# bao1x register map
Vendor: baochip; File version: 1.0
Registers are 32-bit, read-write, reset 0x0 unless marked. A register's access mark holds for its fields unless they carry their own. Offsets are from the block's base; [hi:lo] are bit positions; <NAME> marks a mode.

## UDMA_SCIF
Base 0x50111000
0x00 REG_RX_SADDR — See `udma_scif_reg.sv <https://github.com/baochip/baochip-1x/blob/main/rtl/modul es/ifsub/rtl/udma_scif_reg.sv>`__
  [11:0] r_rx_startaddr
0x04 REG_RX_SIZE — See `udma_scif_reg.sv <https://github.com/baochip/baochip-1x/blob/main/rtl/modul es/ifsub/rtl/udma_scif_reg.sv>`__
  [15:0] r_rx_size
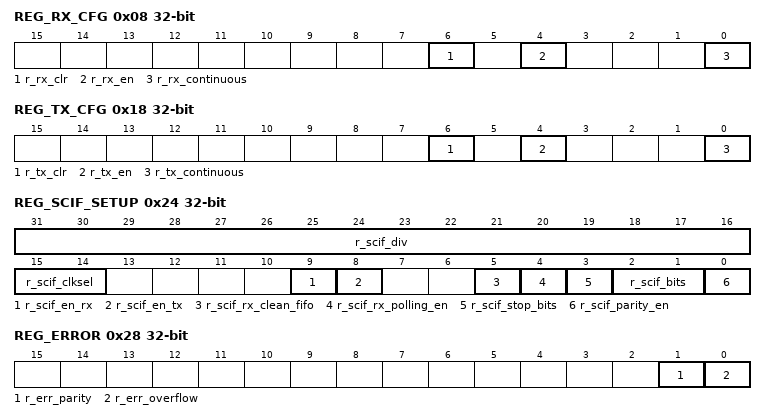
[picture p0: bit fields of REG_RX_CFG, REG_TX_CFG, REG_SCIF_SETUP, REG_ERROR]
0x08 REG_RX_CFG — See `udma_scif_reg.sv <https://github.com/baochip/baochip-1x/blob/main/rtl/modul es/ifsub/rtl/udma_scif_reg.sv>`__
  [6] r_rx_clr, [4] r_rx_en, [0] r_rx_continuous
0x10 REG_TX_SADDR — See `udma_scif_reg.sv <https://github.com/baochip/baochip-1x/blob/main/rtl/modul es/ifsub/rtl/udma_scif_reg.sv>`__
  [11:0] r_tx_startaddr
0x14 REG_TX_SIZE — See `udma_scif_reg.sv <https://github.com/baochip/baochip-1x/blob/main/rtl/modul es/ifsub/rtl/udma_scif_reg.sv>`__
  [15:0] r_tx_size
0x18 REG_TX_CFG — See `udma_scif_reg.sv <https://github.com/baochip/baochip-1x/blob/main/rtl/modul es/ifsub/rtl/udma_scif_reg.sv>`__
  [6] r_tx_clr, [4] r_tx_en, [0] r_tx_continuous
0x20 REG_STATUS — See `udma_scif_reg.sv <https://github.com/baochip/baochip-1x/blob/main/rtl/modul es/ifsub/rtl/udma_scif_reg.sv>`__
  [0] status_i
0x24 REG_SCIF_SETUP — See `udma_scif_reg.sv <https://github.com/baochip/baochip-1x/blob/main/rtl/modul es/ifsub/rtl/udma_scif_reg.sv>`__
  [31:16] r_scif_div, [15:14] r_scif_clksel, [9] r_scif_en_rx, [8] r_scif_en_tx, [5] r_scif_rx_clean_fifo, [4] r_scif_rx_polling_en, [3] r_scif_stop_bits, [2:1] r_scif_bits, [0] r_scif_parity_en
0x28 REG_ERROR — See `udma_scif_reg.sv <https://github.com/baochip/baochip-1x/blob/main/rtl/modul es/ifsub/rtl/udma_scif_reg.sv>`__
  [1] r_err_parity, [0] r_err_overflow
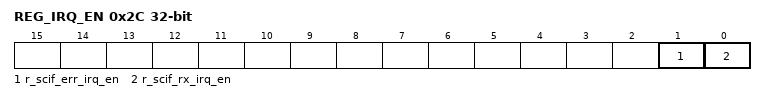
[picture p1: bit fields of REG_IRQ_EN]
0x2C REG_IRQ_EN — See `udma_scif_reg.sv <https://github.com/baochip/baochip-1x/blob/main/rtl/modul es/ifsub/rtl/udma_scif_reg.sv>`__
  [1] r_scif_err_irq_en, [0] r_scif_rx_irq_en
0x30 REG_VALID — See `udma_scif_reg.sv <https://github.com/baochip/baochip-1x/blob/main/rtl/modul es/ifsub/rtl/udma_scif_reg.sv>`__
  [0] r_scif_rx_data_valid
0x34 REG_DATA — See `udma_scif_reg.sv <https://github.com/baochip/baochip-1x/blob/main/rtl/modul es/ifsub/rtl/udma_scif_reg.sv>`__
  [7:0] r_scif_rx_data
0x38 REG_SCIF_ETU — See `udma_scif_reg.sv <https://github.com/baochip/baochip-1x/blob/main/rtl/modul es/ifsub/rtl/udma_scif_reg.sv>`__
  [15:0] r_scif_etu

## UDMA_SPIS_0
Base 0x50112000
Same registers: UDMA_SPIS_1 0x50113000
0x00 REG_RX_SADDR — See `udma_spis_reg.sv <https://github.com/baochip/baochip-1x/blob/main/rtl/modul es/ifsub/rtl/udma_spis_reg.sv>`__
  [11:0] r_rx_startaddr
0x04 REG_RX_SIZE — See `udma_spis_reg.sv <https://github.com/baochip/baochip-1x/blob/main/rtl/modul es/ifsub/rtl/udma_spis_reg.sv>`__
  [15:0] r_rx_size
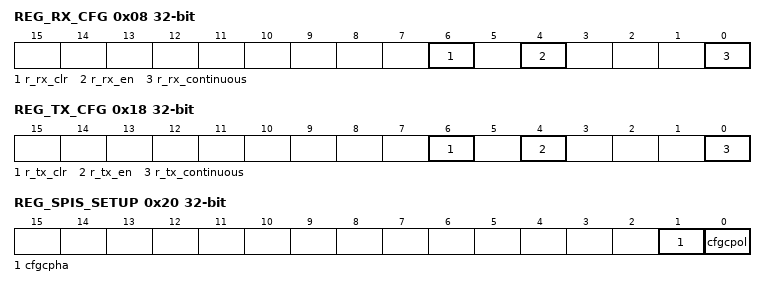
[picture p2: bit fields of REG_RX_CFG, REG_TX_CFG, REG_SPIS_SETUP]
0x08 REG_RX_CFG — See `udma_spis_reg.sv <https://github.com/baochip/baochip-1x/blob/main/rtl/modul es/ifsub/rtl/udma_spis_reg.sv>`__
  [6] r_rx_clr, [4] r_rx_en, [0] r_rx_continuous
0x10 REG_TX_SADDR — See `udma_spis_reg.sv <https://github.com/baochip/baochip-1x/blob/main/rtl/modul es/ifsub/rtl/udma_spis_reg.sv>`__
  [11:0] r_tx_startaddr
0x14 REG_TX_SIZE — See `udma_spis_reg.sv <https://github.com/baochip/baochip-1x/blob/main/rtl/modul es/ifsub/rtl/udma_spis_reg.sv>`__
  [15:0] r_tx_size
0x18 REG_TX_CFG — See `udma_spis_reg.sv <https://github.com/baochip/baochip-1x/blob/main/rtl/modul es/ifsub/rtl/udma_spis_reg.sv>`__
  [6] r_tx_clr, [4] r_tx_en, [0] r_tx_continuous
0x20 REG_SPIS_SETUP — See `udma_spis_reg.sv <https://github.com/baochip/baochip-1x/blob/main/rtl/modul es/ifsub/rtl/udma_spis_reg.sv>`__
  [1] cfgcpha, [0] cfgcpol
0x24 REG_SEOT_CNT — See `udma_spis_reg.sv <https://github.com/baochip/baochip-1x/blob/main/rtl/modul es/ifsub/rtl/udma_spis_reg.sv>`__
  [15:0] sr_seot_cnt
0x28 REG_SPIS_IRQ_EN — See `udma_spis_reg.sv <https://github.com/baochip/baochip-1x/blob/main/rtl/modul es/ifsub/rtl/udma_spis_reg.sv>`__
  [0] seot_irq_en
0x2C REG_SPIS_RXCNT — See `udma_spis_reg.sv <https://github.com/baochip/baochip-1x/blob/main/rtl/modul es/ifsub/rtl/udma_spis_reg.sv>`__
  [15:0] cfgrxcnt
0x30 REG_SPIS_TXCNT — See `udma_spis_reg.sv <https://github.com/baochip/baochip-1x/blob/main/rtl/modul es/ifsub/rtl/udma_spis_reg.sv>`__
  [15:0] cfgtxcnt
0x34 REG_SPIS_DMCNT — See `udma_spis_reg.sv <https://github.com/baochip/baochip-1x/blob/main/rtl/modul es/ifsub/rtl/udma_spis_reg.sv>`__
  [15:0] cfgdmcnt
